# f28004x_dcsm_bank1_z2_regs register map
Vendor: Texas Instruments
Peripheral module from a debugger description file (folder C2000).
Address unit: 16 bits
Registers are 32-bit, read-only, no defined reset value unless marked. A register's access mark holds for its fields unless they carry their own. Offsets are as the file gives them; lines under a group give offsets from that group; [hi:lo] are bit positions; {n}, {i} and the like mark numbered series; 'fields as' and 'values as' point back to an identical list; <NAME> marks a mode.

## DCSM_BANK1_Z2_REGS — DCSM BANK1 Z2 Registers
0x00 B1_Z2_LINKPOINTER_1 — Zone 2 Link Pointer for flash BANK1
  [28:0] LINKPOINTER — Zone2 LINK Pointer in Flash BANK1
0x06 B1_Z2_LINKPOINTERERR_1 — Link Pointer Error for flash BANK1
  [28:0] Z2_LINKPOINTERERR — Error to Resolve Z2 Link pointer from OTP loaded values
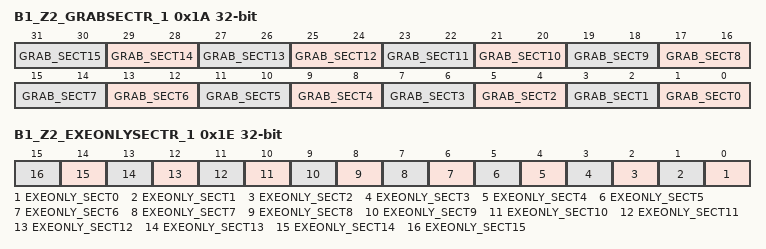
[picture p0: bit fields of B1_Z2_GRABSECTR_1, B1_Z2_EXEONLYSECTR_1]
0x1A B1_Z2_GRABSECTR_1 — Zone 2 Grab Flash BANK1 Sectors Register
  [2n+1:2n] GRAB_SECT{n} (n=0..15) — Grab Flash Sector {n} in Flash BANK1
0x1E B1_Z2_EXEONLYSECTR_1 — Zone 2 Flash BANK1 Execute_Only Sector Register
  [n] EXEONLY_SECT{n} (n=0..15) — Execute-Only Flash Sector {n} in Flash BANK1
